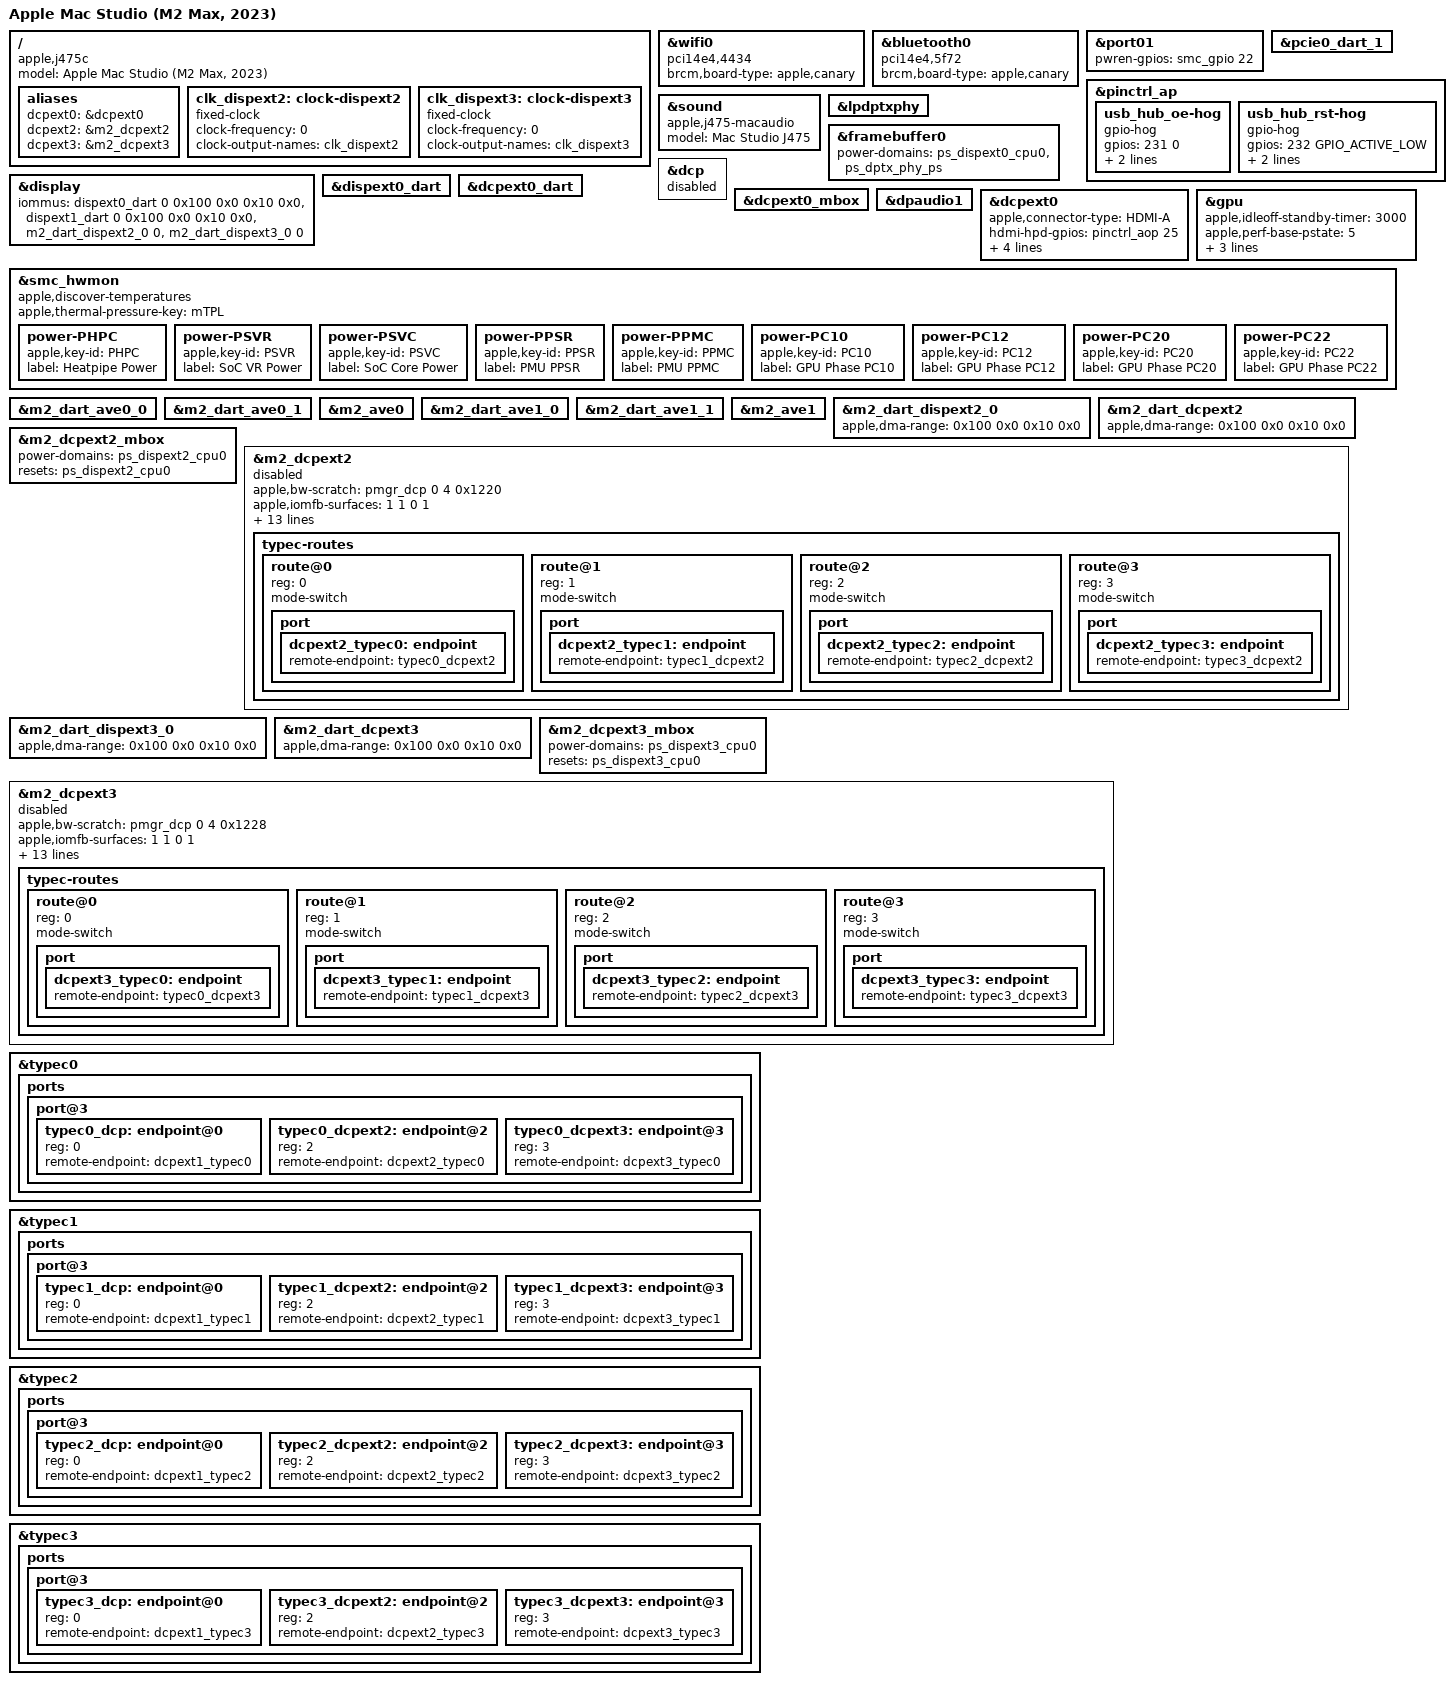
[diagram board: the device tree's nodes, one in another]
// SPDX-License-Identifier: GPL-2.0+ OR MIT
/*
 * Mac Studio (M2 Max, 2023)
 *
 * target-type: J475c
 *
 * Copyright The Asahi Linux Contributors
 */

/dts-v1/;

#include "t6021.dtsi"
#include "t602x-j474-j475.dtsi"

/ {
	compatible = "apple,j475c", "apple,t6021", "apple,arm-platform";
	model = "Apple Mac Studio (M2 Max, 2023)";
};

&wifi0 {
	compatible = "pci14e4,4434";
	brcm,board-type = "apple,canary";
};

&bluetooth0 {
	compatible = "pci14e4,5f72";
	brcm,board-type = "apple,canary";
};

/* enable PCIe port01 with SDHCI */
&port01 {
	pwren-gpios = <&smc_gpio 22 GPIO_ACTIVE_HIGH>;
	status = "okay";
};

&pcie0_dart_1 {
	status = "okay";
};

&pinctrl_ap {
	usb_hub_oe-hog {
		gpio-hog;
		gpios = <231 0>;
		input;
		line-name = "usb-hub-oe";
	};

	usb_hub_rst-hog {
		gpio-hog;
		gpios = <232 GPIO_ACTIVE_LOW>;
		output-low;
		line-name = "usb-hub-rst";
	};
};

&sound {
	compatible = "apple,j475-macaudio", "apple,j375-macaudio", "apple,macaudio";
	model = "Mac Studio J475";
};

&lpdptxphy {
	status = "okay";
};


#define USE_DCPEXT0 1

#if USE_DCPEXT0
/ {
	aliases {
		dcpext0 = &dcpext0;
		/delete-property/ dcp;
	};
};

&framebuffer0 {
	power-domains = <&ps_dispext0_cpu0>, <&ps_dptx_phy_ps>;
};

&dcp {
	status = "disabled";
};
&display {
	iommus = <&dispext0_dart 0 0x100 0x0 0x10 0x0>, <&dispext1_dart 0 0x100 0x0 0x10 0x0>;
};
&dispext0_dart {
	status = "okay";
};
&dcpext0_dart {
	status = "okay";
};
&dcpext0_mbox {
	status = "okay";
};
&dpaudio1 {
	status = "okay";
};
&dcpext0 {
#else
&dpaudio0 {
	status = "okay";
};
&dcp {
#endif
	status = "okay";
	apple,connector-type = "HDMI-A";

	/*  HDMI HPD gpio, used as interrupt*/
	hdmi-hpd-gpios = <&pinctrl_aop 25 GPIO_ACTIVE_HIGH>;

	hdmi-pwren-gpios = <&smc_gpio 23 GPIO_ACTIVE_HIGH>;
	dp2hdmi-pwren-gpios = <&smc_gpio 25 GPIO_ACTIVE_HIGH>;

	phys = <&lpdptxphy>;
	phy-names = "dp-phy";
	apple,dptx-phy = <4>;
};

&gpu {
	apple,idleoff-standby-timer = <3000>;
	apple,perf-base-pstate = <5>;
	apple,perf-boost-ce-step = <100>;
	apple,perf-boost-min-util = <75>;
	apple,perf-tgt-utilization = <70>;
};

#include "hwmon-fan-dual.dtsi"

/*
 * Expose every readable float T* SMC key (labelled by key name) so the
 * J475c sensors can be verified without a curated table. Discovery rejects
 * DT temperature channels, so drop the shared NAND node (TH0x is still
 * discovered automatically).
 */
&smc_hwmon {
	apple,discover-temperatures;
	apple,thermal-pressure-key = "mTPL";
	/delete-node/ temperature-TH0x;

	power-PHPC {
		apple,key-id = "PHPC";
		label = "Heatpipe Power";
	};

	power-PSVR {
		apple,key-id = "PSVR";
		label = "SoC VR Power";
	};

	power-PSVC {
		apple,key-id = "PSVC";
		label = "SoC Core Power";
	};

	power-PPSR {
		apple,key-id = "PPSR";
		label = "PMU PPSR";
	};

	power-PPMC {
		apple,key-id = "PPMC";
		label = "PMU PPMC";
	};

	power-PC10 {
		apple,key-id = "PC10";
		label = "GPU Phase PC10";
	};

	power-PC12 {
		apple,key-id = "PC12";
		label = "GPU Phase PC12";
	};

	power-PC20 {
		apple,key-id = "PC20";
		label = "GPU Phase PC20";
	};

	power-PC22 {
		apple,key-id = "PC22";
		label = "GPU Phase PC22";
	};
};

#include "t6021-peripherals.dtsi"

#include "t6021-j475c-peripherals.dtsi"

/*
 * Both video encoders. The boot loader hands each the firmware iBoot
 * preloads; without that handoff the encoder is disabled.
 */
&m2_dart_ave0_0 {
	status = "okay";
};

&m2_dart_ave0_1 {
	status = "okay";
};

&m2_ave0 {
	status = "okay";
};

&m2_dart_ave1_0 {
	status = "okay";
};

&m2_dart_ave1_1 {
	status = "okay";
};

&m2_ave1 {
	status = "okay";
};

/*
 * Enable dcpext2 and dcpext3 as additional USB-C display pipelines so the
 * Studio can drive three displays (HDMI on dcpext0 plus two rear USB-C ports,
 * or three rear USB-C ports). The peripheral nodes are defined disabled in
 * t6021-j475c-peripherals.dtsi. Keep m2_dcpext2 and m2_dcpext3 disabled here:
 * aura reserves their firmware, sets apple,firmware-compat, and enables each
 * dcpextN alias whose IOP exists in the ADT; an "okay" dcpext that cannot
 * probe would leave the Type-C muxes unregistered and stall every rear port.
 */
/ {
	aliases {
		dcpext2 = &m2_dcpext2;
		dcpext3 = &m2_dcpext3;
	};

	clk_dispext2: clock-dispext2 {
		compatible = "fixed-clock";
		#clock-cells = <0>;
		clock-frequency = <0>;
		clock-output-names = "clk_dispext2";
	};

	clk_dispext3: clock-dispext3 {
		compatible = "fixed-clock";
		#clock-cells = <0>;
		clock-frequency = <0>;
		clock-output-names = "clk_dispext3";
	};
};

&display {
	iommus = <&dispext0_dart 0 0x100 0x0 0x10 0x0>,
		 <&dispext1_dart 0 0x100 0x0 0x10 0x0>,
		 <&m2_dart_dispext2_0 0>,
		 <&m2_dart_dispext3_0 0>;
};

&m2_dart_dispext2_0 {
	apple,dma-range = <0x100 0x0 0x10 0x0>;
	status = "okay";
};

&m2_dart_dcpext2 {
	apple,dma-range = <0x100 0x0 0x10 0x0>;
	status = "okay";
};

&m2_dcpext2_mbox {
	power-domains = <&ps_dispext2_cpu0>;
	resets = <&ps_dispext2_cpu0>;
	status = "okay";
};

&m2_dcpext2 {
	apple,bw-scratch = <&pmgr_dcp 0 4 0x1220>;
	apple,iomfb-surfaces = <1 1 0 1>;
	resets = <&ps_dispext2_cpu0>;
	clocks = <&clk_dispext2>;
	apple,dcp-index = <3>;
	apple,connector-type = "USB-C";
	phys = <&atcphy0 PHY_TYPE_DP>, <&atcphy1 PHY_TYPE_DP>,
	       <&atcphy2 PHY_TYPE_DP>, <&atcphy3 PHY_TYPE_DP>;
	phy-names = "typec0", "typec1", "typec2", "typec3";
	mux-controls = <&atcphy0_xbar 0>, <&atcphy1_xbar 0>,
		       <&atcphy2_xbar 0>, <&atcphy3_xbar 0>;
	mux-control-names = "typec0", "typec1", "typec2", "typec3";
	apple,typec-mux-indices = <4 4 4 4>;
	apple,typec-dptx-phys = <0 1 2 3>;
	status = "disabled";

	typec-routes {
		#address-cells = <1>;
		#size-cells = <0>;

		route@0 {
			reg = <0>;
			mode-switch;

			port {
				dcpext2_typec0: endpoint {
					remote-endpoint = <&typec0_dcpext2>;
				};
			};
		};

		route@1 {
			reg = <1>;
			mode-switch;

			port {
				dcpext2_typec1: endpoint {
					remote-endpoint = <&typec1_dcpext2>;
				};
			};
		};

		route@2 {
			reg = <2>;
			mode-switch;

			port {
				dcpext2_typec2: endpoint {
					remote-endpoint = <&typec2_dcpext2>;
				};
			};
		};

		route@3 {
			reg = <3>;
			mode-switch;

			port {
				dcpext2_typec3: endpoint {
					remote-endpoint = <&typec3_dcpext2>;
				};
			};
		};
	};
};

&m2_dart_dispext3_0 {
	apple,dma-range = <0x100 0x0 0x10 0x0>;
	status = "okay";
};

&m2_dart_dcpext3 {
	apple,dma-range = <0x100 0x0 0x10 0x0>;
	status = "okay";
};

&m2_dcpext3_mbox {
	power-domains = <&ps_dispext3_cpu0>;
	resets = <&ps_dispext3_cpu0>;
	status = "okay";
};

&m2_dcpext3 {
	apple,bw-scratch = <&pmgr_dcp 0 4 0x1228>;
	apple,iomfb-surfaces = <1 1 0 1>;
	resets = <&ps_dispext3_cpu0>;
	clocks = <&clk_dispext3>;
	apple,dcp-index = <4>;
	apple,connector-type = "USB-C";
	phys = <&atcphy0 PHY_TYPE_DP>, <&atcphy1 PHY_TYPE_DP>,
	       <&atcphy2 PHY_TYPE_DP>, <&atcphy3 PHY_TYPE_DP>;
	phy-names = "typec0", "typec1", "typec2", "typec3";
	mux-controls = <&atcphy0_xbar 0>, <&atcphy1_xbar 0>,
		       <&atcphy2_xbar 0>, <&atcphy3_xbar 0>;
	mux-control-names = "typec0", "typec1", "typec2", "typec3";
	apple,typec-mux-indices = <6 6 6 6>;
	apple,typec-dptx-phys = <0 1 2 3>;
	status = "disabled";

	typec-routes {
		#address-cells = <1>;
		#size-cells = <0>;

		route@0 {
			reg = <0>;
			mode-switch;

			port {
				dcpext3_typec0: endpoint {
					remote-endpoint = <&typec0_dcpext3>;
				};
			};
		};

		route@1 {
			reg = <1>;
			mode-switch;

			port {
				dcpext3_typec1: endpoint {
					remote-endpoint = <&typec1_dcpext3>;
				};
			};
		};

		route@2 {
			reg = <2>;
			mode-switch;

			port {
				dcpext3_typec2: endpoint {
					remote-endpoint = <&typec2_dcpext3>;
				};
			};
		};

		route@3 {
			reg = <3>;
			mode-switch;

			port {
				dcpext3_typec3: endpoint {
					remote-endpoint = <&typec3_dcpext3>;
				};
			};
		};
	};
};

&typec0 {
	ports {
		port@3 {
			#address-cells = <1>;
			#size-cells = <0>;
			/delete-node/ endpoint;

			typec0_dcp: endpoint@0 {
				reg = <0>;
				remote-endpoint = <&dcpext1_typec0>;
			};

			typec0_dcpext2: endpoint@2 {
				reg = <2>;
				remote-endpoint = <&dcpext2_typec0>;
			};

			typec0_dcpext3: endpoint@3 {
				reg = <3>;
				remote-endpoint = <&dcpext3_typec0>;
			};
		};
	};
};

&typec1 {
	ports {
		port@3 {
			#address-cells = <1>;
			#size-cells = <0>;
			/delete-node/ endpoint;

			typec1_dcp: endpoint@0 {
				reg = <0>;
				remote-endpoint = <&dcpext1_typec1>;
			};

			typec1_dcpext2: endpoint@2 {
				reg = <2>;
				remote-endpoint = <&dcpext2_typec1>;
			};

			typec1_dcpext3: endpoint@3 {
				reg = <3>;
				remote-endpoint = <&dcpext3_typec1>;
			};
		};
	};
};

&typec2 {
	ports {
		port@3 {
			#address-cells = <1>;
			#size-cells = <0>;
			/delete-node/ endpoint;

			typec2_dcp: endpoint@0 {
				reg = <0>;
				remote-endpoint = <&dcpext1_typec2>;
			};

			typec2_dcpext2: endpoint@2 {
				reg = <2>;
				remote-endpoint = <&dcpext2_typec2>;
			};

			typec2_dcpext3: endpoint@3 {
				reg = <3>;
				remote-endpoint = <&dcpext3_typec2>;
			};
		};
	};
};

&typec3 {
	ports {
		port@3 {
			#address-cells = <1>;
			#size-cells = <0>;
			/delete-node/ endpoint;

			typec3_dcp: endpoint@0 {
				reg = <0>;
				remote-endpoint = <&dcpext1_typec3>;
			};

			typec3_dcpext2: endpoint@2 {
				reg = <2>;
				remote-endpoint = <&dcpext2_typec3>;
			};

			typec3_dcpext3: endpoint@3 {
				reg = <3>;
				remote-endpoint = <&dcpext3_typec3>;
			};
		};
	};
};
